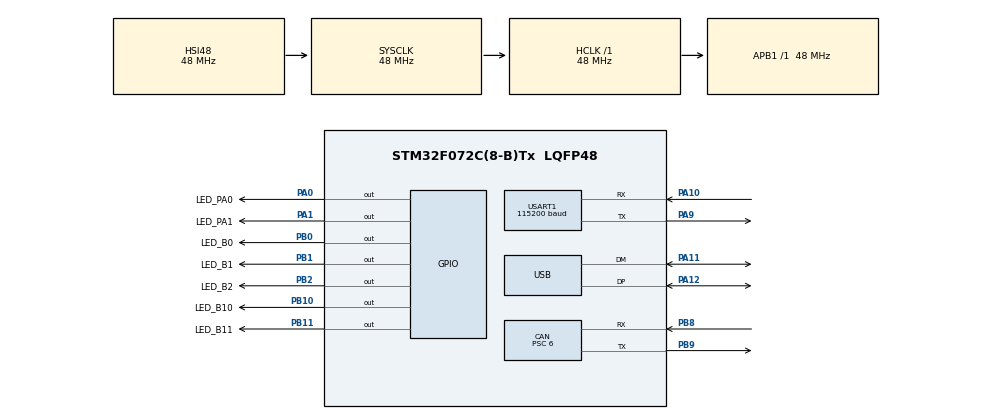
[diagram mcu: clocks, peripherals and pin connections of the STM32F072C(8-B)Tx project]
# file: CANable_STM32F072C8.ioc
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CAN.BS1=CAN_BS1_13TQ
CAN.BS2=CAN_BS2_2TQ
CAN.CalculateBaudRate=500000
CAN.CalculateTimeBit=2000
CAN.CalculateTimeQuantum=125.0
CAN.Mode=CAN_MODE_NORMAL
CAN.Prescaler=6
Dma.Request0=USART1_RX
Dma.Request1=USART1_TX
Dma.USART1_RX.0.Direction=DMA_PERIPH_TO_MEMORY
Dma.USART1_RX.0.Instance=DMA1_Channel3
Dma.USART1_RX.0.MemDataAlignment=DMA_MDATAALIGN_BYTE
Dma.USART1_RX.0.MemInc=DMA_MINC_ENABLE
Dma.USART1_RX.0.Mode=DMA_CIRCULAR
Dma.USART1_RX.0.PeriphDataAlignment=DMA_PDATAALIGN_BYTE
Dma.USART1_RX.0.PeriphInc=DMA_PINC_DISABLE
Dma.USART1_RX.0.Priority=DMA_PRIORITY_LOW
Dma.USART1_TX.1.Direction=DMA_MEMORY_TO_PERIPH
Dma.USART1_TX.1.Instance=DMA1_Channel2
Dma.USART1_TX.1.MemDataAlignment=DMA_MDATAALIGN_BYTE
Dma.USART1_TX.1.MemInc=DMA_MINC_ENABLE
Dma.USART1_TX.1.Mode=DMA_NORMAL
Dma.USART1_TX.1.PeriphDataAlignment=DMA_PDATAALIGN_BYTE
Dma.USART1_TX.1.PeriphInc=DMA_PINC_DISABLE
Dma.USART1_TX.1.Priority=DMA_PRIORITY_LOW
Mcu.Family=STM32F0
Mcu.Name=STM32F072C(8-B)Tx
Mcu.Package=LQFP48
NVIC.CEC_CAN_IRQn=true\:0\:0\:false\:false\:true\:true\:true\:true
NVIC.DMA1_Channel2_3_IRQn=true\:0\:0\:false\:false\:true\:false\:true\:true
NVIC.USART1_IRQn=true\:0\:0\:false\:false\:true\:true\:true\:true
NVIC.USB_IRQn=true\:0\:0\:false\:false\:true\:false\:true\:true
PA0.GPIO_Label=LED_PA0
PA0.PinState=GPIO_PIN_RESET
PA0.Signal=GPIO_Output
PA1.GPIO_Label=LED_PA1
PA1.PinState=GPIO_PIN_RESET
PA1.Signal=GPIO_Output
PA10.Mode=Asynchronous
PA10.Signal=USART1_RX
PA11.Mode=Device
PA11.Signal=USB_DM
PA12.Mode=Device
PA12.Signal=USB_DP
PA13.Mode=Serial_Wire
PA13.Signal=SYS_SWDIO
PA14.Mode=Serial_Wire
PA14.Signal=SYS_SWCLK
PA9.Mode=Asynchronous
PA9.Signal=USART1_TX
PB0.GPIO_Label=LED_B0
PB0.PinState=GPIO_PIN_RESET
PB0.Signal=GPIO_Output
PB1.GPIO_Label=LED_B1
PB1.PinState=GPIO_PIN_RESET
PB1.Signal=GPIO_Output
PB10.GPIO_Label=LED_B10
PB10.Signal=GPIO_Output
PB11.GPIO_Label=LED_B11
PB11.Signal=GPIO_Output
PB2.GPIO_Label=LED_B2
PB2.Signal=GPIO_Output
PB8.Mode=CAN_Activate
PB8.Signal=CAN_RX
PB9.Mode=CAN_Activate
PB9.Signal=CAN_TX
ProjectManager.HeapSize=0x200
ProjectManager.StackSize=0x400
ProjectManager.TargetToolchain=STM32CubeIDE
RCC.AHBFreq_Value=48000000
RCC.APB1Freq_Value=48000000
RCC.APB1TimFreq_Value=48000000
RCC.HCLKFreq_Value=48000000
RCC.PLLDivider=RCC_PREDIV_DIV2
RCC.PLLSourceVirtual=RCC_PLLSOURCE_HSI48
RCC.SYSCLKFreq_VALUE=48000000
RCC.SYSCLKSource=RCC_SYSCLKSOURCE_HSI48
USART1.BaudRate=115200
USART1.VirtualMode-Asynchronous=VM_ASYNC
USB_DEVICE.CLASS_NAME_FS=CDC
USB_DEVICE.VirtualMode=Cdc
USB_DEVICE.VirtualModeFS=Cdc_FS
VP_USB_DEVICE_VS_USB_DEVICE_CDC_FS.Mode=CDC_FS
board=custom

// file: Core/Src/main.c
/* USER CODE BEGIN Header */
/**
  ******************************************************************************
  * @file           : main.c
  * @brief          : Main program body
  ******************************************************************************
  * @attention
  *
  * Copyright (c) 2025 STMicroelectronics.
  * All rights reserved.
  *
  * This software is licensed under terms that can be found in the LICENSE file
  * in the root directory of this software component.
  * If no LICENSE file comes with this software, it is provided AS-IS.
  *
  ******************************************************************************
  */
/* USER CODE END Header */
#include "main.h"
#include "usb_device.h"

/* USER CODE BEGIN Includes */
#ifdef CANABLE_GS_USB
#include "gs_can.h"
#include "usbd_gs_usb.h"
#endif

/* USER CODE END Includes */

CAN_HandleTypeDef hcan;

UART_HandleTypeDef huart1;
DMA_HandleTypeDef hdma_usart1_rx;
DMA_HandleTypeDef hdma_usart1_tx;

void SystemClock_Config(void);
static void MX_GPIO_Init(void);
#ifndef BLUEPILL
static void MX_DMA_Init(void);
#endif
static void MX_CAN_Init(void);
#ifndef BLUEPILL
static void MX_USART1_UART_Init(void);
#endif

int main(void)
{

  /* MCU Configuration--------------------------------------------------------*/

  /* Reset of all peripherals, Initializes the Flash interface and the Systick. */
  HAL_Init();

  /* Configure the system clock */
  SystemClock_Config();

  /* Initialize all configured peripherals */
  MX_GPIO_Init();
#ifndef BLUEPILL
  MX_DMA_Init();
#endif
  MX_CAN_Init();
#ifdef CANABLE_GS_USB
  GS_CAN_Init();
#endif
  MX_USB_DEVICE_Init();
#ifndef BLUEPILL
  MX_USART1_UART_Init();
#endif

  /* Infinite loop */
  /* USER CODE BEGIN WHILE */
#ifndef CANABLE_GS_USB
  PollingInit();
#endif
  while (1)
  {
#ifdef CANABLE_GS_USB
      TimerCallbackPoll(&timerCallback);
      GS_CAN_Poll();
      USBD_GS_USB_Poll(&hUsbDeviceFS);
#else
	  PollingRoutine();
#endif
    /* USER CODE END WHILE */

  }
}

void SystemClock_Config(void)
{
  RCC_OscInitTypeDef RCC_OscInitStruct = {0};
  RCC_ClkInitTypeDef RCC_ClkInitStruct = {0};
  RCC_PeriphCLKInitTypeDef PeriphClkInit = {0};

  /** Initializes the RCC Oscillators according to the specified parameters
  * in the RCC_OscInitTypeDef structure.
  */
  RCC_OscInitStruct.OscillatorType = RCC_OSCILLATORTYPE_HSI48;
  RCC_OscInitStruct.HSI48State = RCC_HSI48_ON;
  RCC_OscInitStruct.PLL.PLLState = RCC_PLL_NONE;
  if (HAL_RCC_OscConfig(&RCC_OscInitStruct) != HAL_OK)
  {
    Error_Handler();
  }

  /** Initializes the CPU, AHB and APB buses clocks
  */
  RCC_ClkInitStruct.ClockType = RCC_CLOCKTYPE_HCLK|RCC_CLOCKTYPE_SYSCLK
                              |RCC_CLOCKTYPE_PCLK1;
  RCC_ClkInitStruct.SYSCLKSource = RCC_SYSCLKSOURCE_HSI48;
  RCC_ClkInitStruct.AHBCLKDivider = RCC_SYSCLK_DIV1;
  RCC_ClkInitStruct.APB1CLKDivider = RCC_HCLK_DIV1;

  if (HAL_RCC_ClockConfig(&RCC_ClkInitStruct, FLASH_LATENCY_1) != HAL_OK)
  {
    Error_Handler();
  }
  PeriphClkInit.PeriphClockSelection = RCC_PERIPHCLK_USB|RCC_PERIPHCLK_USART1;
  PeriphClkInit.Usart1ClockSelection = RCC_USART1CLKSOURCE_PCLK1;
  PeriphClkInit.UsbClockSelection = RCC_USBCLKSOURCE_HSI48;

  if (HAL_RCCEx_PeriphCLKConfig(&PeriphClkInit) != HAL_OK)
  {
    Error_Handler();
  }
}

static void MX_CAN_Init(void)
{

  hcan.Instance = CAN;
  hcan.Init.Prescaler = 6;
  hcan.Init.Mode = CAN_MODE_NORMAL;
  hcan.Init.SyncJumpWidth = CAN_SJW_1TQ;
  hcan.Init.TimeSeg1 = CAN_BS1_13TQ;
  hcan.Init.TimeSeg2 = CAN_BS2_2TQ;
  hcan.Init.TimeTriggeredMode = DISABLE;
  hcan.Init.AutoBusOff = DISABLE;
  hcan.Init.AutoWakeUp = DISABLE;
  hcan.Init.AutoRetransmission = DISABLE;
  hcan.Init.ReceiveFifoLocked = DISABLE;
  hcan.Init.TransmitFifoPriority = DISABLE;
  if (HAL_CAN_Init(&hcan) != HAL_OK)
  {
    Error_Handler();
  }

}

#ifndef BLUEPILL
static void MX_USART1_UART_Init(void)
{

  huart1.Instance = USART1;
  huart1.Init.BaudRate = 115200;
  huart1.Init.WordLength = UART_WORDLENGTH_8B;
  huart1.Init.StopBits = UART_STOPBITS_1;
  huart1.Init.Parity = UART_PARITY_NONE;
  huart1.Init.Mode = UART_MODE_TX_RX;
  huart1.Init.HwFlowCtl = UART_HWCONTROL_NONE;
  huart1.Init.OverSampling = UART_OVERSAMPLING_16;
  huart1.Init.OneBitSampling = UART_ONE_BIT_SAMPLE_DISABLE;
  huart1.AdvancedInit.AdvFeatureInit = UART_ADVFEATURE_NO_INIT;
  if (HAL_UART_Init(&huart1) != HAL_OK)
  {
    Error_Handler();
  }

}

static void MX_DMA_Init(void)
{

  /* DMA controller clock enable */
  __HAL_RCC_DMA1_CLK_ENABLE();

  /* DMA interrupt init */
  /* DMA1_Channel2_3_IRQn interrupt configuration */
  HAL_NVIC_SetPriority(DMA1_Channel2_3_IRQn, 0, 0);
  HAL_NVIC_EnableIRQ(DMA1_Channel2_3_IRQn);

}
#endif

static void MX_GPIO_Init(void)
{
  GPIO_InitTypeDef GPIO_InitStruct = {0};

  /* GPIO Ports Clock Enable */
#ifdef BLUEPILL
  __HAL_RCC_GPIOA_CLK_ENABLE(); /* USB on PA11/PA12. */
  __HAL_RCC_GPIOC_CLK_ENABLE();

  /* The on-board PC13 LED is active low; start with it off. */
  HAL_GPIO_WritePin(LED_ACTIVITY_GPIO_Port, LED_ACTIVITY_Pin, GPIO_PIN_SET);
  GPIO_InitStruct.Pin = LED_ACTIVITY_Pin;
  GPIO_InitStruct.Mode = GPIO_MODE_OUTPUT_PP;
  GPIO_InitStruct.Pull = GPIO_NOPULL;
  GPIO_InitStruct.Speed = GPIO_SPEED_FREQ_LOW;
  HAL_GPIO_Init(LED_ACTIVITY_GPIO_Port, &GPIO_InitStruct);
#else
  __HAL_RCC_GPIOA_CLK_ENABLE();
  __HAL_RCC_GPIOB_CLK_ENABLE();

  /*Configure GPIO pin Output Level */
  HAL_GPIO_WritePin(GPIOA, LED_PA0_Pin|LED_PA1_Pin, GPIO_PIN_RESET);

  /*Configure GPIO pin Output Level */
  HAL_GPIO_WritePin(GPIOB, LED_B0_Pin|LED_B1_Pin|LED_B2_Pin|LED_B10_Pin
                          |LED_B11_Pin, GPIO_PIN_RESET);

  /*Configure GPIO pins : LED_PA0_Pin LED_PA1_Pin */
  GPIO_InitStruct.Pin = LED_PA0_Pin|LED_PA1_Pin;
  GPIO_InitStruct.Mode = GPIO_MODE_OUTPUT_PP;
  GPIO_InitStruct.Pull = GPIO_NOPULL;
  GPIO_InitStruct.Speed = GPIO_SPEED_FREQ_LOW;
  HAL_GPIO_Init(GPIOA, &GPIO_InitStruct);

  /*Configure GPIO pins : LED_B0_Pin LED_B1_Pin LED_B2_Pin LED_B10_Pin
                           LED_B11_Pin */
  GPIO_InitStruct.Pin = LED_B0_Pin|LED_B1_Pin|LED_B2_Pin|LED_B10_Pin
                          |LED_B11_Pin;
  GPIO_InitStruct.Mode = GPIO_MODE_OUTPUT_PP;
  GPIO_InitStruct.Pull = GPIO_NOPULL;
  GPIO_InitStruct.Speed = GPIO_SPEED_FREQ_LOW;
  HAL_GPIO_Init(GPIOB, &GPIO_InitStruct);
#endif

}

void Error_Handler(void)
{
  __disable_irq();
  while (1)
  {
  }
}
